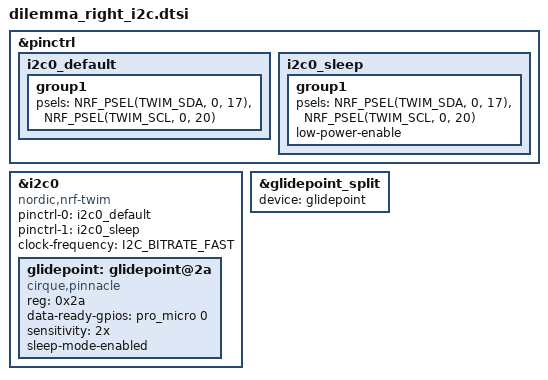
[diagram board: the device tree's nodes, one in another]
/*
 * Copyright (c) 2021 The ZMK Contributors
 *
 * SPDX-License-Identifier: MIT
 */

#include <input/processors.dtsi>
#include <dt-bindings/zmk/input_transform.h>
#include "dilemma.dtsi"

// Configure custom i2c for the Right side

&pinctrl {
    i2c0_default: i2c0_default {
        group1 {
            psels = <NRF_PSEL(TWIM_SDA, 0, 17)>,
                <NRF_PSEL(TWIM_SCL, 0, 20)>;
			// bias-pull-up; //replaced by physical resistors, since it was not stable
        };
    };

    i2c0_sleep: i2c0_sleep {
        group1 {
            psels = <NRF_PSEL(TWIM_SDA, 0, 17)>,
                <NRF_PSEL(TWIM_SCL, 0, 20)>;
            low-power-enable;
			// bias-pull-up; //replaced by physical resistors, since it was not stable
        };
    };
};

cirque_pinnacle_i2c: &i2c0 {
    compatible = "nordic,nrf-twim";
    pinctrl-0 = <&i2c0_default>;
    pinctrl-1 = <&i2c0_sleep>;
    pinctrl-names = "default", "sleep";
    clock-frequency = <I2C_BITRATE_FAST>;
};

// Enable custom i2c for the Right side

&cirque_pinnacle_i2c {
    status = "okay";

    glidepoint: glidepoint@2a {
        compatible = "cirque,pinnacle";
        reg = <0x2a>;
        status = "okay";
        // Pin marked as Serial in the Dilemma PCB (008/D0) is connected to the S pin in the TRRS footprint, 
        // so connecting this S pin to the DR pin in the Cirque, 
        // will make the MCU be notified when there is data ready in the cirque
        data-ready-gpios = <&pro_micro 0 (GPIO_ACTIVE_HIGH)>;
        sensitivity = "2x";
        sleep-mode-enabled; 
    };
};

// Cirque Trackpad

&glidepoint {
	status = "okay";
};

// Cirque Trackpad, if the Left side is central, comment otherwise

&glidepoint_split {
	device = <&glidepoint>;
};

// Cirque Trackpad, if the Right side is central, comment otherwise

// / {
// 	glidepoint_listener: glidepoint_listener {
// 		compatible = "zmk,input-listener";
// 		status = "okay";
// 		device = <&glidepoint>;
//         input-processors = <&zip_xy_transform (INPUT_TRANSFORM_XY_SWAP | INPUT_TRANSFORM_X_INVERT | INPUT_TRANSFORM_Y_INVERT)>, <&zip_xy_scaler 3 2>;
// 	};
// };
